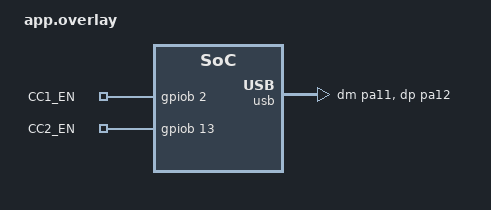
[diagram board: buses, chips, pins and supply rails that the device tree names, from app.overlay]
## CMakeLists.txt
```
# SPDX-License-Identifier: Apache-2.0

set(BOARD google_twinkie_v2)

cmake_minimum_required(VERSION 3.20.0)
find_package(Zephyr REQUIRED HINTS $ENV{ZEPHYR_BASE})
project(google_twinkie)

FILE(GLOB app_sources src/*.c)
target_sources(app PRIVATE ${app_sources})
```

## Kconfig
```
# Private config options for eSPI sample app

# Copyright (c) 2019 Intel Corporation
# SPDX-License-Identifier: Apache-2.0

config STM32_UCPD
        bool "USBC TCPC device controller driver"
        depends on SOC_FAMILY_STM32
        default y
	select USE_STM32_LL_BUS
	select USE_STM32_LL_SYSTEM
	select USE_STM32_LL_RCC
	select USE_STM32_LL_DMA
        select USE_STM32_LL_UCPD
	select USE_STM32_LL_USB
	select USE_STM32_HAL_PCD
	select USE_STM32_HAL_PCD_EX
        help
          Enable USBC TCPC support on the STM32 G0, G4, L5, and U5 family of
          processors.

source "Kconfig.zephyr"
```

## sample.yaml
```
# This file is provided so that the application can be compiled using Twister,
# the Zephyr testing tool. In this file, multiple combinations can be specified,
# so that you can easily test all of them locally or in CI.
sample:
  description: Example application
  name: example-application 
common:
  build_only: true
  integration_platforms:
    - google_twinkie_v2
tests:
  app.default: {}
```

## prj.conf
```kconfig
CONFIG_SMF=y

CONFIG_USB_DEVICE_STACK=y
CONFIG_USB_DEVICE_SN="123456789"
CONFIG_USB_DEVICE_MANUFACTURER="Google LLC"
CONFIG_USB_DEVICE_PRODUCT="Twinkie V2"
CONFIG_USB_DEVICE_VID=0x18d1
CONFIG_USB_DEVICE_PID=5213

CONFIG_USB_DEVICE_STACK=y
CONFIG_USB_COMPOSITE_DEVICE=y
CONFIG_USB_CDC_ACM_RINGBUF_SIZE=512

CONFIG_STDOUT_CONSOLE=y
CONFIG_SERIAL=y
CONFIG_CONSOLE=y
CONFIG_UART_CONSOLE=y
# CONFIG_UART_LINE_CTRL=y
CONFIG_UART_INTERRUPT_DRIVEN=y

CONFIG_PRINTK=y
CONFIG_SHELL=y
# CONFIG_SHELL_MINIMAL=y
CONFIG_SHELL_STACK_SIZE=1024
CONFIG_SHELL_BACKEND_SERIAL=y

CONFIG_THREAD_MONITOR=y
CONFIG_INIT_STACKS=y
CONFIG_BOOT_BANNER=n
CONFIG_THREAD_NAME=y
CONFIG_CBPRINTF_NANO=y

CONFIG_ADC=y
CONFIG_ADC_STM32=y
CONFIG_ADC_SHELL=y
# CONFIG_SENSOR=y
CONFIG_GPIO=y

CONFIG_USB_DC_STM32=n
```

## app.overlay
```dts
/ {
	chosen {
		zephyr,shell_uart = &cdc_acm_uart0;
		zephyr,console = &cdc_acm_uart1;
	};

	cc_config {
		compatible = "gpio-leds";
		cc1_en: cc1en {
			gpios = <&gpiob 2 GPIO_ACTIVE_HIGH>;
			label = "CC1_EN";
		};

		cc2_en: cc2en {
			gpios = <&gpiob 13 GPIO_ACTIVE_HIGH>;
			label = "CC2_EN";
		};
	};
	
	aliases {
		encc1 = &cc1_en;
		encc2 = &cc2_en;
	};
};

zephyr_udc0: &usb {
	/* Twinkie V2 Command Shell */
	cdc_acm_uart0: cdc_acm_uart0 {
		compatible = "zephyr,cdc-acm-uart";
		label = "CDC_ACM_0";
	};

	/* Twinkie V2 Packet Logging */
	cdc_acm_uart1: cdc_acm_uart1 {
		compatible = "zephyr,cdc-acm-uart";
		label = "CDC_ACM_1";
	};

	pinctrl-0 = <&usb_dm_pa11 &usb_dp_pa12>;
	pinctrl-names = "default";
	status = "okay";
};
```

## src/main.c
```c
/*
 * Copyright (c) 2022 The Chromium OS Authors
 *
 * SPDX-License-Identifier: Apache-2.0
 */

#include <zephyr/kernel.h>
#include <zephyr/smf.h>
#include <zephyr/drivers/gpio.h>

#include <zephyr/logging/log.h>
#include <zephyr/usb/usb_device.h>
#include <zephyr/device.h>
#include <zephyr/drivers/uart.h>
#include <zephyr/shell/shell.h>

#include "controls.h"
#include "meas.h"
#include "view.h"
#include "model.h"

int main(void)
{
	const struct device *dev_pd_analyzer = DEVICE_DT_GET(DT_CHOSEN(zephyr_console));

	if (usb_enable(NULL)) {
		return -1;
	}

	meas_init();
	controls_init();
	model_init(dev_pd_analyzer);
	view_init();

	return 0;
}
```

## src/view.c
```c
/*
 * Copyright (c) 2022 The Chromium OS Authors
 *
 * SPDX-License-Identifier: Apache-2.0
 */

#include <zephyr/kernel.h>
#include <zephyr/smf.h>
#include <zephyr/drivers/gpio.h>

#include <zephyr/logging/log.h>
#include <zephyr/usb/usb_device.h>
#include <zephyr/device.h>
#include <zephyr/drivers/uart.h>
#include <zephyr/shell/shell.h>

#include "controls.h"
#include "meas.h"
#include "view.h"
#include "model.h"

LOG_MODULE_REGISTER(main);

#define DEBUG 1

/* The devicetree node identifier for the led aliases. */
#define LED0_NODE DT_ALIAS(led0)
#define LED1_NODE DT_ALIAS(led1)
#define LED2_NODE DT_ALIAS(led2)

/* various flags for the current state of the snooper */
#define FLAGS_SNOOP0		0
#define FLAGS_SNOOP1		1
#define FLAGS_SNOOP2		2
#define FLAGS_SNOOP3		3
#define FLAGS_NO_CONNECTION	4
#define FLAGS_CC1_CONNECTION	5
#define FLAGS_CC2_CONNECTION	6

static const struct gpio_dt_spec led0 = GPIO_DT_SPEC_GET(LED0_NODE, gpios);
static const struct gpio_dt_spec led1 = GPIO_DT_SPEC_GET(LED1_NODE, gpios);
static const struct gpio_dt_spec led2 = GPIO_DT_SPEC_GET(LED2_NODE, gpios);

static const struct smf_state view_states[];

enum led_t {LED_OFF, LED_RED, LED_GREEN, LED_BLUE};
enum view_state_t {SNOOP0, SNOOP1, SNOOP2, SNOOP3};

struct view_obj_t {
	struct smf_ctx ctx;
	k_timeout_t timeout;
	bool toggle;
	atomic_t flags;
} view_obj;

snooper_mask_t get_view_snoop() {
	if (atomic_test_bit(&view_obj.flags, FLAGS_SNOOP0)) return 0;
	if (atomic_test_bit(&view_obj.flags, FLAGS_SNOOP1)) return CC1_CHANNEL_BIT;
	if (atomic_test_bit(&view_obj.flags, FLAGS_SNOOP2)) return CC2_CHANNEL_BIT;
	if (atomic_test_bit(&view_obj.flags, FLAGS_SNOOP3)) return (CC1_CHANNEL_BIT | CC2_CHANNEL_BIT);
	return 0;
}

int view_set_connection(snooper_mask_t vc)
{
	switch (vc) {
	case 0:
		atomic_clear_bit(&view_obj.flags, FLAGS_CC1_CONNECTION);
		atomic_clear_bit(&view_obj.flags, FLAGS_CC2_CONNECTION);
		atomic_set_bit(&view_obj.flags, FLAGS_NO_CONNECTION);
		break;
	case CC1_CHANNEL_BIT:
		atomic_clear_bit(&view_obj.flags, FLAGS_NO_CONNECTION);
		atomic_clear_bit(&view_obj.flags, FLAGS_CC2_CONNECTION);
		atomic_set_bit(&view_obj.flags, FLAGS_CC1_CONNECTION);
		break;
	case CC2_CHANNEL_BIT:
		atomic_clear_bit(&view_obj.flags, FLAGS_NO_CONNECTION);
		atomic_clear_bit(&view_obj.flags, FLAGS_CC1_CONNECTION);
		atomic_set_bit(&view_obj.flags, FLAGS_CC2_CONNECTION);
		break;
	default:
	 	return -EIO;
	}
	return 0;
}

int view_set_snoop(snooper_mask_t vs)
{
	switch (vs) {
	case 0:
		atomic_clear_bit(&view_obj.flags, FLAGS_SNOOP1);
		atomic_clear_bit(&view_obj.flags, FLAGS_SNOOP2);
		atomic_clear_bit(&view_obj.flags, FLAGS_SNOOP3);
		atomic_set_bit(&view_obj.flags, FLAGS_SNOOP0);
		break;
	case CC1_CHANNEL_BIT:
		atomic_clear_bit(&view_obj.flags, FLAGS_SNOOP0);
		atomic_clear_bit(&view_obj.flags, FLAGS_SNOOP2);
		atomic_clear_bit(&view_obj.flags, FLAGS_SNOOP3);
		atomic_set_bit(&view_obj.flags, FLAGS_SNOOP1);
		break;
	case CC2_CHANNEL_BIT:
		atomic_clear_bit(&view_obj.flags, FLAGS_SNOOP0);
		atomic_clear_bit(&view_obj.flags, FLAGS_SNOOP1);
		atomic_clear_bit(&view_obj.flags, FLAGS_SNOOP3);
		atomic_set_bit(&view_obj.flags, FLAGS_SNOOP2);
		break;
	case (CC1_CHANNEL_BIT | CC2_CHANNEL_BIT):
		atomic_clear_bit(&view_obj.flags, FLAGS_SNOOP0);
		atomic_clear_bit(&view_obj.flags, FLAGS_SNOOP1);
		atomic_clear_bit(&view_obj.flags, FLAGS_SNOOP2);
		atomic_set_bit(&view_obj.flags, FLAGS_SNOOP3);
		break;
	default:
	 	return -EIO;
	}

	view_set_connection(0);
	return 0;
}

static void set_led(enum led_t led)
{
	switch (led) {
	case LED_OFF:
		gpio_pin_set_dt(&led0, 0);
		gpio_pin_set_dt(&led1, 0);
		gpio_pin_set_dt(&led2, 0);
		break;
	case LED_RED:
		gpio_pin_set_dt(&led0, 1);
		gpio_pin_set_dt(&led1, 0);
		gpio_pin_set_dt(&led2, 0);
		break;
	case LED_GREEN:
		gpio_pin_set_dt(&led0, 0);
		gpio_pin_set_dt(&led1, 1);
		gpio_pin_set_dt(&led2, 0);
		break;
	case LED_BLUE:
		gpio_pin_set_dt(&led0, 0);
		gpio_pin_set_dt(&led1, 0);
		gpio_pin_set_dt(&led2, 1);
		break;
	}
}

static void snoop0_entry(void *o)
{
	struct view_obj_t *vo = (struct view_obj_t *)o;

	set_led(LED_OFF);
	vo->timeout = K_MSEC(1000);
}

static void snoop0_run(void *o)
{
	struct view_obj_t *vo = (struct view_obj_t *)o;

	if (atomic_test_bit(&vo->flags, FLAGS_SNOOP1)) {
		smf_set_state(SMF_CTX(vo), &view_states[SNOOP1]);
	} else if (atomic_test_bit(&vo->flags, FLAGS_SNOOP2)) {
		smf_set_state(SMF_CTX(vo), &view_states[SNOOP2]);
	} else if (atomic_test_bit(&vo->flags, FLAGS_SNOOP3)) {
		smf_set_state(SMF_CTX(vo), &view_states[SNOOP3]);
	}
}

static void snoop0_exit(void *o)
{
}

static void snoop1_entry(void *o)
{
	struct view_obj_t *vo = (struct view_obj_t *)o;

	vo->timeout = K_MSEC(1000);
}

static void snoop1_run(void *o)
{
	struct view_obj_t *vo = (struct view_obj_t *)o;

	if (atomic_test_bit(&vo->flags, FLAGS_SNOOP0)) {
		smf_set_state(SMF_CTX(vo), &view_states[SNOOP0]);
	} else if (atomic_test_bit(&vo->flags, FLAGS_SNOOP2)) {
		smf_set_state(SMF_CTX(vo), &view_states[SNOOP2]);
	} else if (atomic_test_bit(&vo->flags, FLAGS_SNOOP3)) {
		smf_set_state(SMF_CTX(vo), &view_states[SNOOP3]);
	} else if (atomic_test_bit(&vo->flags, FLAGS_NO_CONNECTION)) {
		if (vo->toggle) {
			set_led(LED_BLUE);
			vo->toggle = false;
		} else {
			set_led(LED_OFF);
			vo->toggle = true;
		}
	} else if (atomic_test_bit(&vo->flags, FLAGS_CC1_CONNECTION)) {
		set_led(LED_GREEN);
	} else if (atomic_test_bit(&vo->flags, FLAGS_CC2_CONNECTION)) {
		set_led(LED_RED);
	}
}

static void snoop1_exit(void *o)
{
	set_led(LED_OFF);
}

static void snoop2_entry(void *o)
{
	struct view_obj_t *vo = (struct view_obj_t *)o;

	vo->timeout = K_MSEC(500);
}

static void snoop2_run(void *o)
{
	struct view_obj_t *vo = (struct view_obj_t *)o;

	if (atomic_test_bit(&vo->flags, FLAGS_SNOOP0)) {
		smf_set_state(SMF_CTX(vo), &view_states[SNOOP0]);
	} else if (atomic_test_bit(&vo->flags, FLAGS_SNOOP1)) {
		smf_set_state(SMF_CTX(vo), &view_states[SNOOP1]);
	} else if (atomic_test_bit(&vo->flags, FLAGS_SNOOP3)) {
		smf_set_state(SMF_CTX(vo), &view_states[SNOOP3]);
	} else if (atomic_test_bit(&vo->flags, FLAGS_NO_CONNECTION)) {
		if (vo->toggle) {
			set_led(LED_BLUE);
			vo->toggle = false;
		} else {
			set_led(LED_OFF);
			vo->toggle = true;
		}
	} else if (atomic_test_bit(&vo->flags, FLAGS_CC1_CONNECTION)) {
		set_led(LED_RED);
	} else if (atomic_test_bit(&vo->flags, FLAGS_CC2_CONNECTION)) {
		set_led(LED_GREEN);
	}
}

static void snoop2_exit(void *o)
{
	set_led(LED_OFF);
}

static void snoop3_entry(void *o)
{
	struct view_obj_t *vo = (struct view_obj_t *)o;

	vo->timeout = K_MSEC(250);
}

static void snoop3_run(void *o)
{
	struct view_obj_t *vo = (struct view_obj_t *)o;

	if (atomic_test_bit(&vo->flags, FLAGS_SNOOP0)) {
		smf_set_state(SMF_CTX(vo), &view_states[SNOOP0]);
	} else if (atomic_test_bit(&vo->flags, FLAGS_SNOOP1)) {
		smf_set_state(SMF_CTX(vo), &view_states[SNOOP1]);
	} else if (atomic_test_bit(&vo->flags, FLAGS_SNOOP2)) {
		smf_set_state(SMF_CTX(vo), &view_states[SNOOP2]);
	} else if (atomic_test_bit(&vo->flags, FLAGS_NO_CONNECTION)) {
		if (vo->toggle) {
			set_led(LED_BLUE);
			vo->toggle = false;
		} else {
			set_led(LED_OFF);
			vo->toggle = true;
		}
	} else if (atomic_test_bit(&vo->flags, FLAGS_CC1_CONNECTION)) {
		set_led(LED_GREEN);
	} else if (atomic_test_bit(&vo->flags, FLAGS_CC2_CONNECTION)) {
		set_led(LED_GREEN);
	}
}

static void snoop3_exit(void *o)
{
	set_led(LED_OFF);
}

static const struct smf_state view_states[] = {
	[SNOOP0] = SMF_CREATE_STATE(snoop0_entry, snoop0_run, snoop0_exit),
	[SNOOP1] = SMF_CREATE_STATE(snoop1_entry, snoop1_run, snoop1_exit),
	[SNOOP2] = SMF_CREATE_STATE(snoop2_entry, snoop2_run, snoop2_exit),
	[SNOOP3] = SMF_CREATE_STATE(snoop3_entry, snoop3_run, snoop3_exit),
};

int view_init(void)
{
	int ret;

	if (!device_is_ready(led0.port)) {
		return -EIO;
	}

	if (!device_is_ready(led1.port)) {
		return -EIO;

	}

	if (!device_is_ready(led2.port)) {
		return -EIO;
	}

	ret = gpio_pin_configure_dt(&led0, GPIO_OUTPUT_ACTIVE);
	if (ret < 0) {
		return ret;
	}

	ret = gpio_pin_configure_dt(&led1, GPIO_OUTPUT_ACTIVE);
	if (ret < 0) {
		return ret;
	}

	ret = gpio_pin_configure_dt(&led2, GPIO_OUTPUT_ACTIVE);
	if (ret < 0) {
		return ret;
	}

	view_obj.flags = ATOMIC_INIT(0);

	return 0;
}

void main(void)
{
	const struct device *dev_pd_analyzer = DEVICE_DT_GET(DT_CHOSEN(zephyr_console));

	if (usb_enable(NULL)) {
		return;
	}
/*
	const struct device *dev;
	uint32_t dtr = 0;

	dev = DEVICE_DT_GET(DT_CHOSEN(zephyr_shell_uart));
	if (!device_is_ready(dev) || usb_enable(NULL)) {
		return;
	}

	while (!dtr) {
		uart_line_ctrl_get(dev, UART_LINE_CTRL_DTR, &dtr);
		k_sleep(K_MSEC(100));
	}
*/
	meas_init();
	controls_init();
	model_init(dev_pd_analyzer);
	view_init();

	smf_set_initial(SMF_CTX(&view_obj), &view_states[SNOOP0]);

        while(1) {
                smf_run_state(SMF_CTX(&view_obj));
                k_sleep(view_obj.timeout);
        }
}
```
